# CPDMA register map
Vendor: Texas Instruments
Peripheral module from a debugger description file (folder DRA74xP_75xP_76xP_77xP).
Registers are 32-bit, access per field, reset 0x0 unless marked. A register's access mark holds for its fields unless they carry their own. Offsets are as the file gives them; lines under a group give offsets from that group; [hi:lo] are bit positions; {n}, {i} and the like mark numbered series; 'fields as' and 'values as' point back to an identical list; <NAME> marks a mode.

## CPDMA
0x00 CPDMA_TX_IDVER ro reset not defined — CPDMA_REGS TX revision register
  [31:0] REVISION — CPDMA TX Revision Value
0x04 CPDMA_TX_CONTROL — CPDMA_REGS TX control register
  [0] TX_EN rw — TX Enable 0 - Disabled 1 - Enabled
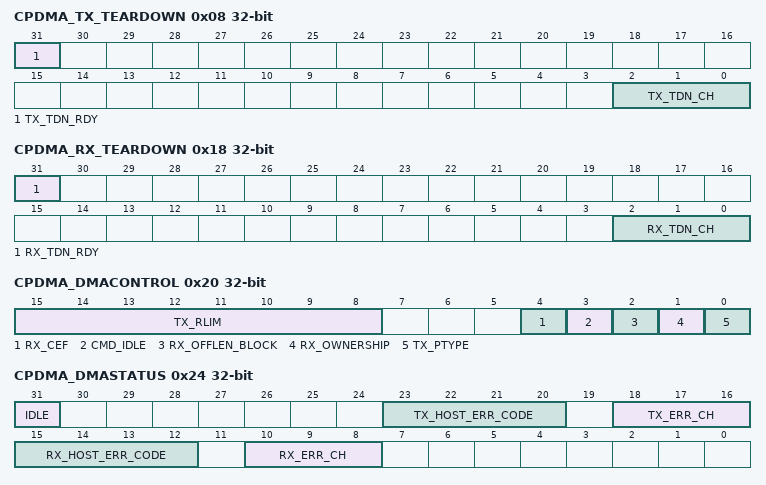
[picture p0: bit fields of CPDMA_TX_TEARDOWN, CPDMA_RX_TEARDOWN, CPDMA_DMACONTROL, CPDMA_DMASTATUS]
0x08 CPDMA_TX_TEARDOWN — CPDMA_REGS TX teardown register
  [31] TX_TDN_RDY ro — Tx Teardown Ready - read as zero, but is always assumed to be one (unused).
  [2:0] TX_TDN_CH rw — Tx Teardown Channel - Transmit channel teardown is commanded by writing the encoded value of the transmit channel to be torn down. The teardown register is read as zero.
0x10 CPDMA_RX_IDVER ro reset not defined — CPDMA_REGS RX revision register
  [31:0] REVISION — RX Revision Value
0x14 CPDMA_RX_CONTROL — CPDMA_REGS RX control register
  [0] RX_EN rw — RX DMA Enable 0 - Disabled 1 - Enabled
0x18 CPDMA_RX_TEARDOWN — CPDMA_REGS RX teardown register
  [31] RX_TDN_RDY ro — Teardown Ready - read as zero, but is always assumed to be one (unused).
  [2:0] RX_TDN_CH rw — Rx Teardown Channel -Receive channel teardown is commanded by writing the encoded value of the receive channel to be torn down. The teardown register is read as zero.
0x1C CPDMA_SOFT_RESET — CPDMA_REGS soft reset register
  [0] SOFT_RESET rw — Software reset - Writing a one to this bit causes the CPDMA logic to be reset. Software reset occurs when the RX and TX DMA Controllers are in an idle state to avoid locking up the VBUSP bus. After writing a one to this bit, it may be polled to determine if the reset has occurred. If a one is read, the reset has not yet occurred. If a zero is read then reset has occurred.
0x20 CPDMA_DMACONTROL — CPDMA_REGS CPDMA control register
  [15:8] TX_RLIM rw — Transmit Rate Limit Channel Bus 00000000 - no rate-limited channels 10000000 - channel 7 is rate-limited 11000000 - channels 7 downto 6 are rate-limited 11100000 - channels 7 downto 5 are rate-limited 11110000 - channels 7 downto 4 are rate-limited 11111000 - channels 7 downto 3 are rate-limited 11111100 - channels 7 downto 2 are rate-limited 11111110 - channels 7 downto 1 are rate-limited 11111111 - channels 7 downto 0 are rate-limited all others invalid - this bus must be set MSB towards LSB. TX_PTYPE must be set if any TX_RLIM bit is set for fixed priority.
  [4] RX_CEF rw — RX Copy Error Frames Enable - Enables DMA overrun frames to be transferred to memory (up to the point of overrun). The overrun error bit will be set in the frame EOP buffer descriptor. Overrun frame data will be filtered when RX_CEF is not set. Frames coming from the receive FIFO with other error bits set are not effected by this bit. 0 - Frames containing overrun errors are filtered. 1 - Frames containing overrun errors are transferred to memory.
  [3] CMD_IDLE rw — Command Idle 0 - Idle not commanded 1 - Idle Commanded (read IDLE in CPDMA_DMASTATUS)
  [2] RX_OFFLEN_BLOCK rw — Receive Offset/Length word write block. 0 - Do not block the DMA writes to the receive buffer descriptor offset/buffer length word. The offset/buffer length word is written as specified in CPPI 3.0. 1 - Block all CPDMA DMA controller writes to the receive buffer descriptor offset/buffer length words during CPPI packet processing. when this bit is set, the CPDMA will never write the third word to any receive buffer descriptor.
  [1] RX_OWNERSHIP rw — Receive Ownership Write Bit Value. 0 - The CPDMA writes the receive ownership bit to zero at the end of packet processing as specified in CPPI 3.0. 1 - The CPDMA writes the receive ownership bit to one at the end of packet processing. Users who do not use the ownership mechanism can use this mode to preclude the necessity of software having to set this bit each time the buffer descriptor is used.
  [0] TX_PTYPE rw — Transmit Queue Priority Type 0 - The queue uses a round robin scheme to select the next channel for transmission. 1 - The queue uses a fixed (channel 7 highest priority) priority scheme to select the next channel for transmission
0x24 CPDMA_DMASTATUS ro — CPDMA_REGS CPDMA status register
  [31] IDLE — Idle Status Bit - Indicates when set that the CPDMA is not transferring a packet on transmit or receive.
  [23:20] TX_HOST_ERR_CODE — TX Host Error Code - This field is set to indicate CPDMA detected TX DMA related host errors. The host should read this field after a HOST_ERR_INT to determine the error. Host error Interrupts require hardware reset in order to recover. A zero packet length is an error, but it is not detected. 0x0 - No error 0x1 - SOP error. 0x2 - Ownership bit not set in SOP buffer. 0x3 - Zero Next Buffer Descriptor Pointer Without EOP 0x4 - Zero Buffer Pointer. 0x5 - Zero Buffer Length 0x6 - Packet Length Error (sum of buffers is less than packet length) 0x7 - 1xF - reserved
  [18:16] TX_ERR_CH — TX Host Error Channel - This field indicates which TX channel (if applicable) the host error occurred on. This field is cleared to zero on a host read.
  [15:12] RX_HOST_ERR_CODE — RX Host Error Code - This field is set to indicate CPDMA detected RX DMA related host errors. The host should read this field after a HOST_ERR_INT to determine the error. Host error Interrupts require hardware reset in order to recover. 0x0 - No error 0x1 - reserved 0x2 - Ownership bit not set in input buffer. 0x3 - reserved 0x4 - Zero Buffer Pointer. 0x5 - Zero buffer length on non-SOP descriptor 0x6 - SOP buffer length not greater than offset 0x7 - 1xF - reserved
  [10:8] RX_ERR_CH — RX Host Error Channel - This field indicates which RX channel the host error occurred on. This field is cleared to zero on a host read.
0x28 CPDMA_RX_BUFFER_OFFSET — CPDMA_REGS receive buffer offset
  [15:0] RX_BUFFER_OFFSET rw — Receive Buffer Offset Value - The RX_BUFFER_OFFSET will be written by the port into each frame SOP buffer descriptor buffer_offset field. The frame data will begin after the rx_buffer_offset value of bytes. A value of 0x0000 indicates that there are no unused bytes at the beginning of the data and that valid data begins on the first byte of the buffer. A value of 0x000F (decimal 15) indicates that the first 15 bytes of the buffer are to be ignored by the port and that valid buffer data starts on byte 16 of the buffer. This value is used for all channels.
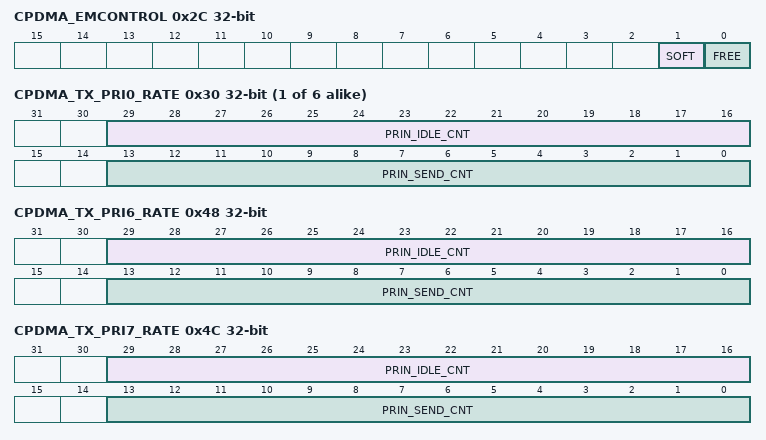
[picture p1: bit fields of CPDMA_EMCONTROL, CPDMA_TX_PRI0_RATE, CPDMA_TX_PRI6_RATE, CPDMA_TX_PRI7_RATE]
0x2C CPDMA_EMCONTROL — CPDMA_REGS emulation control
  [1] SOFT rw — Emulation Soft Bit
  [0] FREE rw — Emulation Free Bit
{0x30+4i} CPDMA_TX_PRI{i}_RATE (i=0..5) — CPDMA_REGS transmit (ingress) priority {i} rate
  [29:16] PRIN_IDLE_CNT rw — Priority ( 7:0) idle count
  [13:0] PRIN_SEND_CNT rw — Priority ( 7:0) send count
0x48 CPDMA_TX_PRI6_RATE — CPDMA_REGS TRANSMIT (INGRESS) PRIORITY 6 RATE
  fields as CPDMA_TX_PRI0_RATE
0x4C CPDMA_TX_PRI7_RATE — CPDMA_REGS transmit (ingress) priority 7 rate
  fields as CPDMA_TX_PRI0_RATE
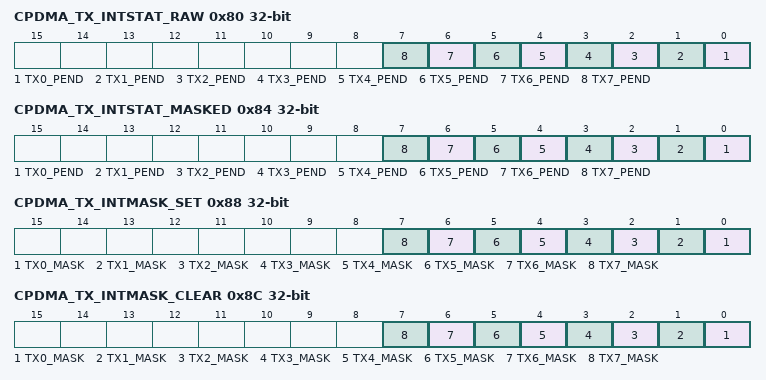
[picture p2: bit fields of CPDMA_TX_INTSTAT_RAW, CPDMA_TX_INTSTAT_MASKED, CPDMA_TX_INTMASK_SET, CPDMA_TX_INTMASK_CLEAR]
0x80 CPDMA_TX_INTSTAT_RAW ro — CPDMA_INT TX interrupt status register (raw value)
  [n] TX{n}_PEND (n=0..7) — TX{n}_PEND raw int read (before mask).
0x84 CPDMA_TX_INTSTAT_MASKED ro — CPDMA_INT TX interrupt status register (masked value)
  [n] TX{n}_PEND (n=0..7) — TX{n}_PEND masked interrupt read.
0x88 CPDMA_TX_INTMASK_SET — CPDMA_INT TX interrupt mask set register
  [n] TX{n}_MASK rw (n=0..7) — TX Channel {n} Mask - Write one to enable interrupt.
0x8C CPDMA_TX_INTMASK_CLEAR — CPDMA_INT TX Interrupt mask clear register
  [n] TX{n}_MASK rw (n=0..7) — TX Channel {n} Mask - Write one to disable interrupt.
0x90 CPDMA_IN_VECTOR ro — CPDMA_INT input vector (read only)
  [31:0] DMA_IN_VECTOR — DMA Input Vector - The value of DMA_IN_VECTOR is reset to zero, but will change to the IN_VECTOR bus value one clock after reset is deasserted. Thereafter, this value will change to a new IN_VECTOR value one clock after the IN_VECTOR value changes.
0x94 CPDMA_EOI_VECTOR — CPDMA_INT end of interrupt vector
  [4:0] DMA_EOI_VECTOR rw — DMA End of Interrupt Vector - The EOI_VECTOR( 4:0) pins reflect the value written to this location one MAIN_CLK cycle after a write to this location. The EOI_WR signal is asserted for a single clock cycle after a latency of two MAIN_CLK cycles when a write is performed to this location.
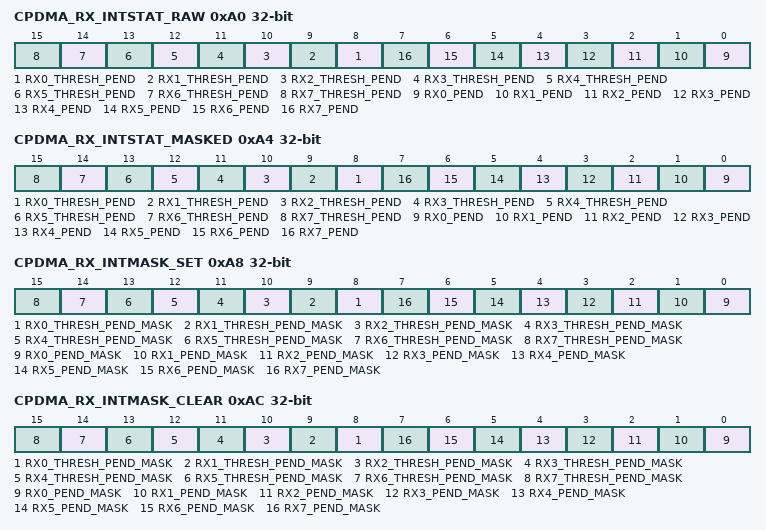
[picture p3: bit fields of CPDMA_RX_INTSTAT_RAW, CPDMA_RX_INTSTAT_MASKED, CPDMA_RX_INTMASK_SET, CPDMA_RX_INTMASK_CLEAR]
0xA0 CPDMA_RX_INTSTAT_RAW ro — CPDMA_INT RX Interrupt status register (raw value)
  [n+8] RX{n}_THRESH_PEND (n=0..7) — RX{n}_THRESH_PEND raw int read (before mask).
  [n] RX{n}_PEND (n=0..7) — RX{n}_PEND raw int read (before mask).
0xA4 CPDMA_RX_INTSTAT_MASKED ro — CPDMA_INT RX interrupt status register (masked value)
  [n+8] RX{n}_THRESH_PEND (n=0..7) — RX{n}_THRESH_PEND masked int read.
  [n] RX{n}_PEND (n=0..7) — RX{n}_PEND masked int read.
0xA8 CPDMA_RX_INTMASK_SET — CPDMA_INT RX interrupt mask set register
  [n+8] RX{n}_THRESH_PEND_MASK rw (n=0..7) — RX Channel {n} Threshold Pending Int. Mask - Write one to enable Int.
  [n] RX{n}_PEND_MASK rw (n=0..7) — RX Channel {n} Pending Int. Mask - Write one to enable Int.
0xAC CPDMA_RX_INTMASK_CLEAR — CPDMA_INT RX interrupt mask clear register
  [n+8] RX{n}_THRESH_PEND_MASK rw (n=0..7) — RX Channel {n} Threshold Pending Int. Mask - Write one to disable Int.
  [n] RX{n}_PEND_MASK rw (n=0..7) — RX Channel {n} Pending Int. Mask - Write one to disable Int.
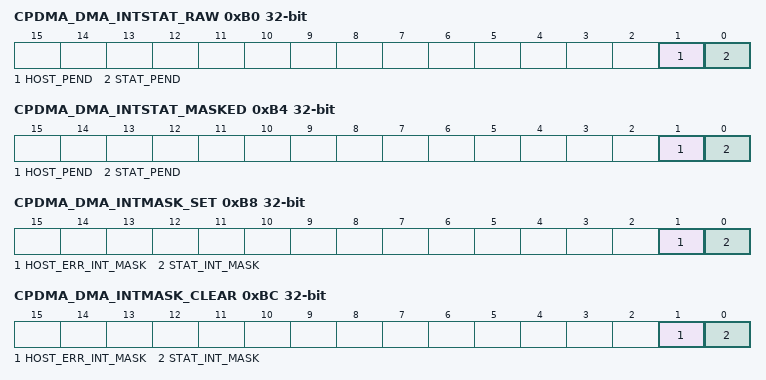
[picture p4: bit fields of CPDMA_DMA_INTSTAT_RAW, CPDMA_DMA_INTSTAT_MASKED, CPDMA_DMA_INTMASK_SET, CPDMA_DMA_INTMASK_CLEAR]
0xB0 CPDMA_DMA_INTSTAT_RAW ro — CPDMA_INT DMA interrupt status register (raw value)
  [1] HOST_PEND — Host Pending Interrupt - raw int read (before mask).
  [0] STAT_PEND — Statistics Pending Interrupt - raw int read (before mask).
0xB4 CPDMA_DMA_INTSTAT_MASKED ro — CPDMA_INT DMA interrupt status register (masked value)
  [1] HOST_PEND — Host Pending Interrupt - masked interrupt read.
  [0] STAT_PEND — Statistics Pending Interrupt - masked interrupt read.
0xB8 CPDMA_DMA_INTMASK_SET — CPDMA_INT DMA interrupt mask set register
  [1] HOST_ERR_INT_MASK wo — Host Error Interrupt Mask - Write one to enable interrupt.
  [0] STAT_INT_MASK ro — Statistics Interrupt Mask - Write one to enable interrupt.
0xBC CPDMA_DMA_INTMASK_CLEAR — CPDMA_INT DMA interrupt mask clear register
  [1] HOST_ERR_INT_MASK rw — Host Error Interrupt Mask - Write one to disable interrupt.
  [0] STAT_INT_MASK rw — Statistics Interrupt Mask - Write one to disable interrupt.
{0xC0+4i} CPDMA_RX{i}_PENDTHRESH (i=0..7) — CPDMA_INT receive threshold pending register channel {i}
  [7:0] RX_PENDTHRESH rw — Rx Flow Threshold - This field contains the threshold value for issuing receive threshold pending interrupts (when enabled).
{0xE0+4i} CPDMA_RX{i}_FREEBUFFER (i=0..7) — CPDMA_INT receive free buffer register channel {i}
  [15:0] RX_FREEBUFFER wo — Rx Free Buffer Count - This field contains the count of free buffers available. TheCPDMA_RX{i}_PENDTHRESH[7:0] RX_PENDTHRESH value is compared with this field to determine if the receive threshold pending interrupt should be asseted (if enabled). This is a write to increment field. This field rolls over to zero on overflow. If receive threshold pending interrupts are used, the host must initialize this field to the number of available buffers (one register per channel). The port decrements (by the number of buffers in the received frame) the associated channel register for each received frame. This is a write to increment field. The host must write this field with the number of buffers that have been freed due to host processing.
